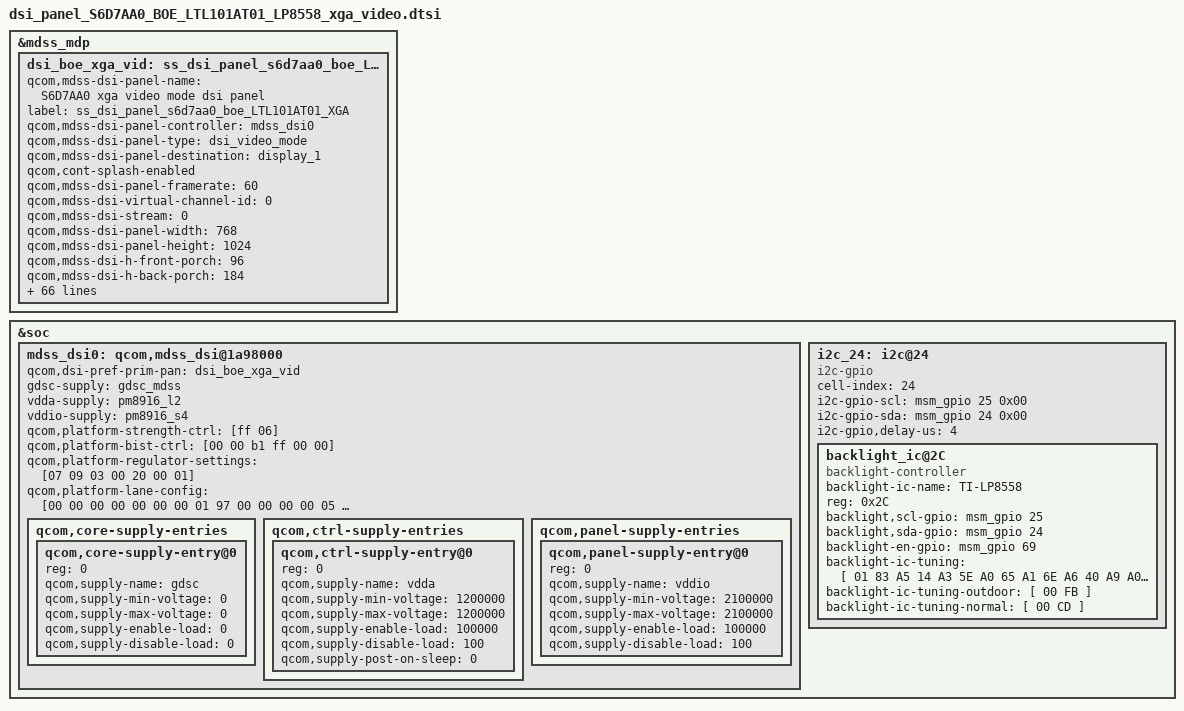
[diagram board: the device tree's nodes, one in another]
/* Copyright (c) 2013, The Linux Foundation. All rights reserved.

 *

 * This program is free software; you can redistribute it and/or modify

 * it under the terms of the GNU General Public License version 2 and

 * only version 2 as published by the Free Software Foundation.

 *

 * This program is distributed in the hope that it will be useful,

 * but WITHOUT ANY WARRANTY; without even the implied warranty of

 * MERCHANTABILITY or FITNESS FOR A PARTICULAR PURPOSE.  See the

 * GNU General Public License for more details.

 */


/*---------------------------------------------------------------------------

 * This file is autogenerated file using gcdb parser. Please do not edit it.

 * Update input XML file to add a new entry or update variable in this file

 * VERSION = "1.0"

 *---------------------------------------------------------------------------*/

&mdss_mdp {

	dsi_boe_xga_vid: ss_dsi_panel_s6d7aa0_boe_LTL101AT01_WXGA {

		qcom,mdss-dsi-panel-name = "S6D7AA0 xga video mode dsi panel";

		label = "ss_dsi_panel_s6d7aa0_boe_LTL101AT01_XGA";

		qcom,mdss-dsi-panel-controller = <&mdss_dsi0>;

		qcom,mdss-dsi-panel-type = "dsi_video_mode";

		qcom,mdss-dsi-panel-destination = "display_1";

		qcom,cont-splash-enabled;

		qcom,mdss-dsi-panel-framerate = <60>;

		qcom,mdss-dsi-virtual-channel-id = <0>;

		qcom,mdss-dsi-stream = <0>;

		qcom,mdss-dsi-panel-width = <768>;

		qcom,mdss-dsi-panel-height = <1024>;

		qcom,mdss-dsi-h-front-porch = <96>;

		qcom,mdss-dsi-h-back-porch = <184>;

		qcom,mdss-dsi-h-pulse-width = <16>;

		qcom,mdss-dsi-h-sync-skew = <0>;

		qcom,mdss-dsi-v-back-porch = <6>;

		qcom,mdss-dsi-v-front-porch = <8>;

		qcom,mdss-dsi-v-pulse-width = <2>;

		qcom,mdss-dsi-h-left-border = <0>;

		qcom,mdss-dsi-h-right-border = <0>;

		qcom,mdss-dsi-v-top-border = <0>;

		qcom,mdss-dsi-v-bottom-border = <0>;

		qcom,mdss-dsi-bpp = <24>;

		qcom,mdss-dsi-underflow-color = <0xff>;

		qcom,mdss-dsi-border-color = <0>;

		qcom,mdss-dsi-on-command = [

               39 01 00 00 00 00 03 F0 5A 5A

               39 01 00 00 00 00 03 F1 5A 5A

               39 01 00 00 00 00 03 FC A5 A5

               39 01 00 00 00 00 03 D0 00 10

               39 01 00 00 00 00 04 C3 40 00 08
               39 01 00 00 00 00 04 BC 01 4E 0B
               39 01 00 00 00 00 06 FD 16 10 11 23 09

               39 01 00 00 00 00 07 FE 00 02 03 21 80 68

               39 01 00 00 00 00 02 B3 51

               39 01 00 00 00 00 02 53 24

               39 01 00 00 0A 00 04 F2 02 08 08

               39 01 00 00 00 00 04 C0 80 80 30

               39 01 00 00 00 00 0E CD 2E 2E 2E 2E 2E 2E 2E 2E 2E 2E 2E 2E 2E

               39 01 00 00 00 00 0E CE 00 00 00 00 00 00 00 00 00 00 00 00 00

               39 01 00 00 00 00 02 C1 03

               05 01 00 00 78 00 02 11 00

               39 00 00 00 00 00 03 F0 A5 A5

               39 01 00 00 00 00 03 F1 A5 A5

               39 01 00 00 00 00 03 FC 5A 5A

               39 01 00 00 00 00 02 35 00
               05 01 00 00 05 00 02 29 00
		];

		qcom,mdss-dsi-off-command = [

					39 01 00 00 00 00 02 22 00

					05 01 00 00 40 00 02 28 00

					05 01 00 00 0A 00 02 10 00

		];

		qcom,mdss-dsi-on-command-state = "dsi_lp_mode";

		qcom,mdss-dsi-off-command-state = "dsi_hs_mode";

		qcom,mdss-dsi-h-sync-pulse = <0>;

		qcom,mdss-dsi-bllp-eof-power-mode;

		qcom,mdss-dsi-bllp-power-mode;

		qcom,mdss-dsi-hbp-power-mode;

		qcom,mdss-dsi-lane-0-state;

		qcom,mdss-dsi-lane-1-state;

		qcom,mdss-dsi-lane-2-state;

		qcom,mdss-dsi-lane-3-state;
		qcom,mdss-dsi-panel-timings = [6A 16 0E 00 38 3A 12 18 10 03 04 00];
		qcom,mdss-dsi-t-clk-post = <0x04>;
		qcom,mdss-dsi-t-clk-pre = <0x23>;
		qcom,mdss-dsi-bl-min-level = <1>;

		qcom,mdss-dsi-bl-max-level = <255>;

		qcom,mdss-dsi-dma-trigger = "trigger_sw";

		qcom,mdss-dsi-mdp-trigger = "none";

		qcom,mdss-dsi-panel-clockrate = <397500000>;

		qcom,mdss-dsi-bl-pmic-control-type = "bl_ctrl_dcs";

		qcom,mdss-dsi-traffic-mode = <2>;
		samsung,mdnie-tuning-enable-tft;
		qcom,esd_irq_gpio = <&msm_gpio 0 0>;

		qcom,esd-check-enabled;

		qcom,mdss-dsi-panel-status-check-mode="reg_read_irq";

		qcom,mdss-dsi-panel-status-value = <1>;

		qcom,mdss-dsi-panel-status-irq-trigger="falling";

		samsung,display_on_tx_cmds_revA = [05 01 00 00 05 00 02 29 00];

		samsung,tft_pwm_tx_cmds_revA=[

			39 01 00 00 00 00 02 51 FF/*First command should be PWM duty change command*/

		];

		samsung,cabc_on_tx_cmds_revA = [

			39 01 00 00 00 00 02 55 03

		];

		samsung,cabc_off_tx_cmds_revA = [

			39 01 00 00 00 00 02 55 00

		];

		/*

		* ************************************************************************************************************************

		* Scaled level to index mappings

		* ************************************************************************************************************************

		*/

		samsung,scaled_level_map_table_revA = <

		/*<idx>	  <from>  <till> <scaled_level> */

			0		0		0		0

			1		1		1		1

			2		2		2		2

			3		3		3		3

			4		4		4		4

			5		5		5		5

			6		6		6		6

			7		7		7		7

			8		8		8		8

			9		9		9		9

			10		10		10		10

			11		11		11		11

			12		12		12		12

			13		13		13		13

			14		14		14		14

			15		15		15		15

			16		16		16		16

			17		17		17		17

			18		18		18		18

			19		19		19		19

			20		20		20		20

			21		21		21		21

			22		22		22		22

			23		23		23		23

			24		24		24		24

			25		25		25		25

			26		26		26		26

			27		27		27		27

			28		28		28		28

			29		29		29		29

			30		30		30		30

			31		31		31		31

			32		32		32		32

			33		33		33		33

			34		34		34		34

			35		35		35		35

			36		36		36		36

			37		37		37		37

			38		38		38		38

			39		39		39		39

			40		40		40		40

			41		41		41		41

			42		42		42		42

			43		43		43		43

			44		44		44		44

			45		45		45		45

			46		46		46		46

			47		47		47		47

			48		48		48		48

			49		49		49		49

			50		50		50		50

			51		51		51		51

			52		52		52		52

			53		53		53		53

			54		54		54		54

			55		55		55		55

			56		56		56		56

			57		57		57		57

			58		58		58		58

			59		59		59		59

			60		60		60		60

			61		61		61		61

			62		62		62		62

			63		63		63		63

			64		64		64		64

			65		65		65		65

			66		66		66		66

			67		67		67		67

			68		68		68		68

			69		69		69		69

			70		70		70		70

			71		71		71		71

			72		72		72		72

			73		73		73		73

			74		74		74		74

			75		75		75		75

			76		76		76		76

			77		77		77		77

			78		78		78		78

			79		79		79		79

			80		80		80		80

			81		81		81		81

			82		82		82		82

			83		83		83		83

			84		84		84		84

			85		85		85		85

			86		86		86		86

			87		87		87		87

			88		88		88		88

			89		89		89		89

			90		90		90		90

			91		91		91		91

			92		92		92		92

			93		93		93		93

			94		94		94		94

			95		95		95		95

			96		96		96		96

			97		97		97		97

			98		98		98		98

			99		99		99		99

			100		100		100		100

			101		101		101		101

			102		102		102		102

			103		103		103		103

			104		104		104		104

			105		105		105		105

			106		106		106		106

			107		107		107		107

			108		108		108		108

			109		109		109		109

			110		110		110		110

			111		111		111		111

			112		112		112		112

			113		113		113		113

			114		114		114		114

			115		115		115		115

			116		116		116		116

			117		117		117		117

			118		118		118		118

			119		119		119		119

			120		120		120		120

			121		121		121		121

			122		122		122		122

			123		123		123		123

			124		124		124		124

			125		125		125		125

			126		126		126		126

			127		127		127		127

			128		128		128		128

			129		129		129		129

			130		130		130		130

			131		131		131		131

			132		132		132		132

			133		133		133		133

			134		134		134		134

			135		135		135		135

			136		136		136		136

			137		137		137		137

			138		138		138		138

			139		139		139		139

			140		140		140		140

			141		141		141		141

			142		142		142		142

			143		143		143		143

			144		144		144		144

			145		145		145		145

			146		146		146		146

			147		147		147		147

			148		148		148		148

			149		149		149		149

			150		150		150		150

			151		151		151		151

			152		152		152		152

			153		153		153		153

			154		154		154		154

			155		155		155		155

			156		156		156		156

			157		157		157		157

			158		158		158		158

			159		159		159		159

			160		160		160		160

			161		161		161		161

			162		162		162		162

			163		163		163		163

			164		164		164		164

			165		165		165		165

			166		166		166		166

			167		167		167		167

			168		168		168		168

			169		169		169		169

			170		170		170		170

			171		171		171		171

			172		172		172		172

			173		173		173		173

			174		174		174		174

			175		175		175		175

			176		176		176		176

			177		177		177		177

			178		178		178		178

			179		179		179		179

			180		180		180		180

			181		181		181		181

			182		182		182		182

			183		183		183		183

			184		184		184		184

			185		185		185		185

			186		186		186		186

			187		187		187		187

			188		188		188		188

			189		189		189		189

			190		190		190		190

			191		191		191		191

			192		192		192		192

			193		193		193		193

			194		194		194		194

			195		195		195		195

			196		196		196		196

			197		197		197		197

			198		198		198		198

			199		199		199		199

			200		200		200		200

			201		201		201		201

			202		202		202		202

			203		203		203		203

			204		204		204		204

			205		205		205		205

			206		206		206		206

			207		207		207		207

			208		208		208		208

			209		209		209		209

			210		210		210		210

			211		211		211		211

			212		212		212		212

			213		213		213		213

			214		214		214		214

			215		215		215		215

			216		216		216		216

			217		217		217		217

			218		218		218		218

			219		219		219		219

			220		220		220		220

			221		221		221		221

			222		222		222		222

			223		223		223		223

			224		224		224		224

			225		225		225		225

			226		226		226		226

			227		227		227		227

			228		228		228		228

			229		229		229		229

			230		230		230		230

			231		231		231		231

			232		232		232		232

			233		233		233		233

			234		234		234		234

			235		235		235		235

			236		236		236		236

			237		237		237		237

			238		238		238		238

			239		239		239		239

			240		240		240		240

			241		241		241		241

			242		242		242		242

			243		243		243		243

			244		244		244		244

			245		245		245		245

			246		246		246		246

			247		247		247		247

			248		248		248		248

			249		249		249		249

			250		250		250		250

			251		251		251		251

			252		252		252		252

			253		253		253		253

			254		254		254		254

			255		255		255		255

		>;

		samsung,tft-common-support;

		samsung,blic-discharging-delay-us = <120000>;

		qcom,mdss-power-off-delay-us = <5000>;

		qcom,mdss-dsi-reset-sequence = <1 20>, <0 20>, <1 20>;

		qcom,mdss-pan-physical-width-dimension = <148>;

		qcom,mdss-pan-physical-height-dimension = <197>;

		qcom,mdss-dsi-lp11-init;

		qcom,mdss-dsi-init-delay-us = <20000>;
		qcom,mdss-dsi-force-clk-lane-hs;
		samsung,panel-vendor = "BOE";
	};

};

&soc {

	mdss_dsi0: qcom,mdss_dsi@1a98000 {

		qcom,dsi-pref-prim-pan = <&dsi_boe_xga_vid>;

		gdsc-supply = <&gdsc_mdss>;

		vdda-supply = <&pm8916_l2>;

		vddio-supply = <&pm8916_s4>;

		qcom,platform-strength-ctrl = [ff 06];

		qcom,platform-bist-ctrl = [00 00 b1 ff 00 00];

		qcom,platform-regulator-settings = [07 09 03 00 20 00 01];

		qcom,platform-lane-config = [00 00 00 00 00 00 00 01 97

			00 00 00 00 05 00 00 01 97

			00 00 00 00 0a 00 00 01 97

			00 00 00 00 0f 00 00 01 97

			00 c0 00 00 00 00 00 01 bb];

		qcom,core-supply-entries {

			#address-cells = <1>;

			#size-cells = <0>;


			qcom,core-supply-entry@0 {

				reg = <0>;

				qcom,supply-name = "gdsc";

				qcom,supply-min-voltage = <0>;

				qcom,supply-max-voltage = <0>;

				qcom,supply-enable-load = <0>;

				qcom,supply-disable-load = <0>;

			};

		};

		qcom,ctrl-supply-entries {

			#address-cells = <1>;

			#size-cells = <0>;


			qcom,ctrl-supply-entry@0 {

				reg = <0>;

				qcom,supply-name = "vdda";

				qcom,supply-min-voltage = <1200000>;

				qcom,supply-max-voltage = <1200000>;

				qcom,supply-enable-load = <100000>;

				qcom,supply-disable-load = <100>;

				qcom,supply-post-on-sleep = <0>;

			};

		};

		qcom,panel-supply-entries {

			#address-cells = <1>;

			#size-cells = <0>;


			qcom,panel-supply-entry@0 {

				reg = <0>;

				qcom,supply-name = "vddio";

				qcom,supply-min-voltage = <2100000>;

				qcom,supply-max-voltage = <2100000>;

				qcom,supply-enable-load = <100000>;

				qcom,supply-disable-load = <100>;

			};

		};

	};

	i2c_24: i2c@24 {


		cell-index = <24>;

		compatible = "i2c-gpio";

		i2c-gpio-scl = <&msm_gpio 25  0x00>; /*scl gpio*/

		i2c-gpio-sda = <&msm_gpio 24 0x00>;  /*sda gpio*/

		i2c-gpio,delay-us = <4>;


		backlight_ic@2C {

			compatible = "backlight-controller";

			backlight-ic-name = "TI-LP8558";

			reg = <0x2C>;

			backlight,scl-gpio = <&msm_gpio 25 0x00>;

			backlight,sda-gpio = <&msm_gpio 24 0x00>;

			backlight-en-gpio = <&msm_gpio 69 0x00>;

			backlight-ic-tuning = [
					01	83
					A5	14
					A3	5E
					A0	65
					A1	6E
					A6	40
					A9	A0
					98	21
					9E	00
					00	CD
			];

			backlight-ic-tuning-outdoor = [

					00  FB

			];
			backlight-ic-tuning-normal = [
					00	CD
			];
		};

	};


};

